# RZT2ME register map
Vendor: Renesas Electronics Corporation; Series: RZT; File version: 1.00.00
CPU: other r0p0, little endian, MPU, no FPU, VTOR, 4 interrupt priority bits, 624 interrupts
Registers are 32-bit, read-write, reset 0x0 unless marked. A register's access mark holds for its fields unless they carry their own. Offsets are from the block's base; [hi:lo] are bit positions; {n}, {i} and the like mark numbered series; 'fields as' and 'values as' point back to an identical list.

## ETHSW (part 1 of 3) — Ethernet Switch
Base 0x80120000
0x00 REVISION ro reset 0x42000600 — Switch Core Version Register
  [31:0] REV — Revision
0x04 SCRATCH
  [31:0] SCRATCH — The Scratch Register provides a memory location to test the register access.
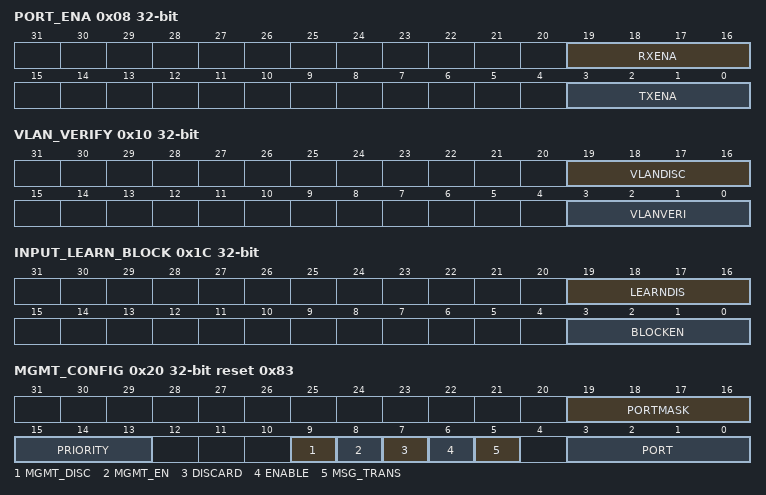
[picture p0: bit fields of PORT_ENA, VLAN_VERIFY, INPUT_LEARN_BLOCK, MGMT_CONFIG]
0x08 PORT_ENA reset not defined — Port Enable Register
  [19:16] RXENA — Receive Enable Mask
  [3:0] TXENA — Transmit Enable Mask
0x0C UCAST_DEFAULT_MASK0 reset 0xF — Unicast Default Mask Register 0
  [3:0] UCASTDM — Default Unicast Resolution
0x10 VLAN_VERIFY — Verify VLAN Domain Register
  [19:16] VLANDISC — Discard Unknown
  [3:0] VLANVERI — Verify VLAN Domain
0x14 BCAST_DEFAULT_MASK0 reset 0xF — Broadcast Default Mask Register 0
  [3:0] BCASTDM — Default Broadcast Resolution
0x18 MCAST_DEFAULT_MASK0 reset 0xF — Multicast Default Mask Register 0
  [3:0] MCASTDM — Default Multicast Resolution
0x1C INPUT_LEARN_BLOCK — Input Learning Block Register
  [19:16] LEARNDIS — Learning Disable
  [3:0] BLOCKEN — Blocking Enable
0x20 MGMT_CONFIG reset 0x83 (reset mask 0xFE0EF) — Management Configuration Register
  [19:16] PORTMASK — Portmask for transmission of management frames. When the management port transmits a frame to the switch, it is forwarded to all ports in this portmask (bit 16 = port 0, bit 17 = port 1, ..., bit 19 = port 3).
  [15:13] PRIORITY — Priority to use for transmitted BPDU frames if non-zero.
  [9] MGMT_DISC — This bit is the same as DISCARD (bit 7) but for the management port.
  [8] MGMT_EN — If set, BPDU frames received at the management port are forwarded to the ports given in the portmask given in this register, bypassing the normal forwarding decisions (except forced forwarding).
  [7] DISCARD — If set, BPDU frames are discarded always.
  [6] ENABLE — If set, all Bridge Protocol Frames (BPDU) are forwarded exclusively to the management port specified in bits [3:0].
  [5] MSG_TRANS — Set (latched) when a BPDU message is transmitted from the management port to any output port. This bit can be used for handshaking to indicate that the port mask bits are used and can now be changed again by setting it to 0.
  [3:0] PORT — The Port number of the port that should act as a management port. Keep the initial value.
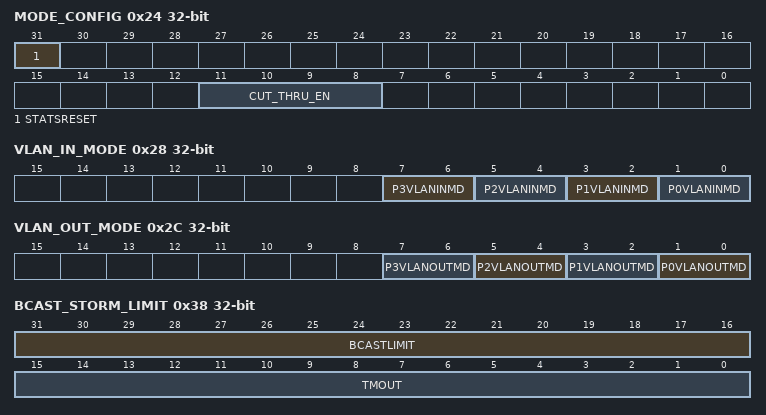
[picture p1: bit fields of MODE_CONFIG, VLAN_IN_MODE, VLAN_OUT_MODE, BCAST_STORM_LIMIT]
0x24 MODE_CONFIG — Mode Configuration Register
  [31] STATSRESET — Reset Statistics Counters Command.
  [11:8] CUT_THRU_EN — Port Cut through Support Enable
0x28 VLAN_IN_MODE — VLAN Input Manipulation Mode Register
  [all] fields
    {v}=Mode {v+1} (v=0..3)
  [7:6] P3VLANINMD — Port3 Define Behavior of VLAN Input Manipulation Function
  [5:4] P2VLANINMD — Port 2 Define Behavior of VLAN Input Manipulation Function
  [3:2] P1VLANINMD — Port 1 Define Behavior of VLAN Input Manipulation Function
  [1:0] P0VLANINMD — Port 0 Define Behavior of VLAN Input Manipulation Function
0x2C VLAN_OUT_MODE — VLAN Output Manipulation Mode Register
  [all] fields
    0=No output manipulation; 1=Mode 1, Strip Mode; 2=Mode 2, Tag Through; 3=Mode 3, Transparent
  [2n+1:2n] P{n}VLANOUTMD (n=0..3) — Port {n} Define Behavior of VLAN Output Manipulation Function
0x30 VLAN_IN_MODE_ENA — VLAN Input Mode Enable Register
  [3:0] VLANINMDEN — Enable the input processing according to the VLAN_IN_MODE for a port (1 bit per port).
0x34 VLAN_TAG_ID reset 0x8100
  [15:0] VLANTAGID — The VLAN type field (TPID) value to expect to identify a VLAN tagged frame.
0x38 BCAST_STORM_LIMIT — Broadcast Storm Protection Register
  [31:16] BCASTLIMIT — Number of broadcast frames (-1) that can be accepted on a port during a timeout period. If more are received, they are discarded. The counter is implemented per port independently. However, the limit is used for all ports.
  [15:0] TMOUT — Timeout in steps of 65535 switch operating clock cycles.
0x3C MCAST_STORM_LIMIT — Multicast Storm Protection Register
  [31:16] MCASTLIMIT — Number of multicast frames (-1) that can be accepted on a port during a timeout period. If more are received, they are discarded. The counter is implemented per port independently. However, the limit is used for all ports.
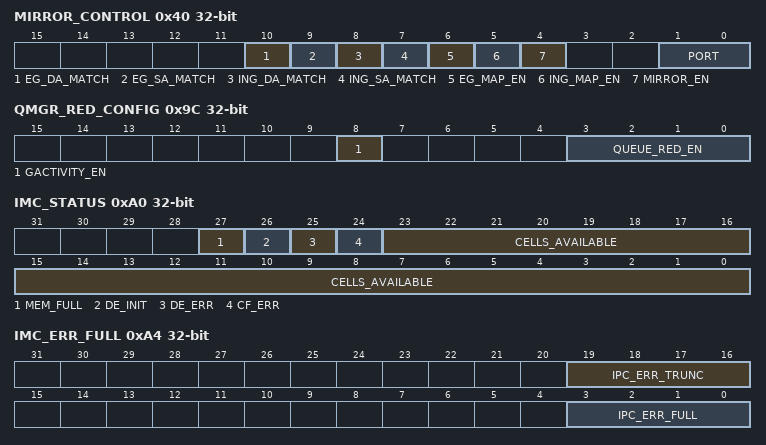
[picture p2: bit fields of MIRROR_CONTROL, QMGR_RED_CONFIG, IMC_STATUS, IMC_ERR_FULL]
0x40 MIRROR_CONTROL — Port Mirroring Configuration Register
  [10] EG_DA_MATCH — If set, only frames transmitted on an egress port with a destination address matching the value programmed in MIRROR_EDST registers are mirrored. Other frames are not mirrored.
  [9] EG_SA_MATCH — If set, only frames transmitted on an egress port with a source address matching the value programmed in MIRROR_ESRC registers are mirrored. Other frames are not mirrored.
  [8] ING_DA_MATCH — If set, only frames received on an ingress port with a destination address matching the value programmed in MIRROR_IDST registers are mirrored. Other frames are not mirrored.
  [7] ING_SA_MATCH — If set, only frames received on an ingress port with a source address matching the value programmed in MIRROR_ISRC registers are mirrored. Other frames are not mirrored.
  [6] EG_MAP_EN — If set, the egress map is enabled (MIRROR_EG_MAP).
  [5] ING_MAP_EN — If set, the ingress map is enabled (MIRROR_ING_MAP).
  [4] MIRROR_EN
    0=Disabled; 1=Enabled
  [1:0] PORT — The port number of the port that acts as the mirror port and receives all mirrored frames. Valid setting range is 0 to 3.
0x44 MIRROR_EG_MAP — Port Mirroring Egress Port Definition Register
  [3:0] EMAP — Port Mirroring Egress Port Definitions
0x48 MIRROR_ING_MAP — Port Mirroring Ingress Port Definition Register
  [3:0] IMAP — Port Mirroring Ingress Port Definitions
0x4C MIRROR_ISRC_0 — Ingress Source MAC Address for Mirror Filtering Register 0
  [31:0] ISRC — Ingress Source MAC Address for Mirror Filtering
0x50 MIRROR_ISRC_1 — Ingress Source MAC Address for Mirror Filtering Register 1
  [15:0] ISRC — Ingress Source MAC Address for Mirror Filtering
0x54 MIRROR_IDST_0 — Ingress Destination MAC Address for Mirror Filtering Register 0
  [31:0] IDST — Ingress Destination MAC Address for Mirror Filtering
0x58 MIRROR_IDST_1 — Ingress Destination MAC Address for Mirror Filtering Register 1
  [15:0] IDST — Ingress Destination MAC Address for Mirror Filtering
0x5C MIRROR_ESRC_0 — Egress Source MAC Address for Mirror Filtering Register 0
  [31:0] ESRC — Egress Source MAC Address for Mirror Filtering
0x60 MIRROR_ESRC_1 — Egress Source MAC Address for Mirror Filtering Register 1
  [15:0] ESRC — Egress Source MAC Address for Mirror Filtering
0x64 MIRROR_EDST_0 — Egress Destination MAC Address for Mirror Filtering Register 0
  [31:0] EDST — Egress Destination MAC Address for Mirror Filtering
0x68 MIRROR_EDST_1 — Egress Destination MAC Address for Mirror Filtering Register 1
  [15:0] EDST — Egress Destination MAC Address for Mirror Filtering
0x6C MIRROR_CNT — Mirror Filtering Count Value Register
  [7:0] CNT — Count Value for Mirror Filtering
0x70 UCAST_DEFAULT_MASK1 reset 0xF — Unicast Default Mask Register 1
  [3:0] UCASTDM1 — Default Unicast Resolution Mask 1
0x74 BCAST_DEFAULT_MASK1 reset 0xF — Broadcast Default Mask Register 1
  [3:0] BCASTDM1 — Default Broadcast Resolution Mask 1
0x78 MCAST_DEFAULT_MASK1 reset 0xF — Multicast Default Mask Register 1
  [3:0] MCASTDM1 — Default Multicast Resolution Mask 1
0x7C PORT_XCAST_MASK_SEL — Port Mask Select Register
  [3:0] MSEL — Mask Select
    0=XCAST_DEFAULT_MASK0 registers are selected; 1=XCAST_DEFAULT_MASK1 registers are selected
0x88 QMGR_ST_MINCELLS — Minimum Memory Cell Statistics Register
  [10:0] STMINCELLS — Minimum Free Cell Indication
0x94 QMGR_RED_MIN4 reset 0xF0F0F0F — RED Minimum Threshold Register
  [31:0] CFGRED_MINTH4 — Random Early Detection (RED) Minimum Threshold for Queues 0 to 3
0x98 QMGR_RED_MAX4 reset 0x2F2F2F2F — RED Maximum Threshold Register
  [31:0] CFGRED_MAXTH4 — Random Early Detection (RED) Maximum Threshold for Queues 0 to 3
0x9C QMGR_RED_CONFIG — RED Configuration Register
  [8] GACTIVITY_EN — Enable Averaging on Global Switch Activity (when this bit is 1) or on port local activity (when this bit is 0) only.
  [3:0] QUEUE_RED_EN — Enable Random Early Detection (RED) (when this bit is 1) or Tail Drop (when this bit is 0) congestion management for a queue.
0xA0 IMC_STATUS ro — Input Memory Controller Status Register
  [27] MEM_FULL — Latched Indication that Memory is or was Full
  [26] DE_INIT — Asserts during Memory Initialization (deallocation module)
  [25] DE_ERR — Deallocation Error
  [24] CF_ERR — Cell Factory Empty Error
  [23:0] CELLS_AVAILABLE — Total number of memory cells (128-byte units) available in the shared memory (real time).
0xA4 IMC_ERR_FULL ro — Input Port Memory Full and Truncation Indicator Register
  [19:16] IPC_ERR_TRUNC — Memory became full while a frame was received and was partly written into memory.
  [3:0] IPC_ERR_FULL — Memory was full at start of a frame reception.
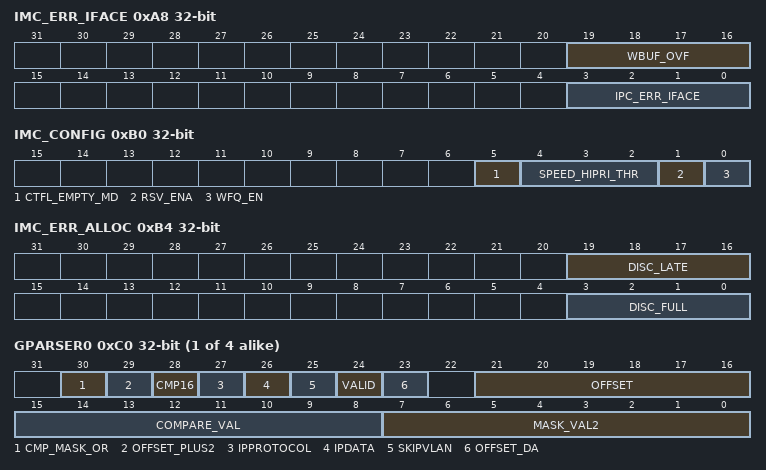
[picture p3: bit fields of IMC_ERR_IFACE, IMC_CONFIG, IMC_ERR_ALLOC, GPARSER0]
0xA8 IMC_ERR_IFACE ro — Input Port Memory Error Indicator Register
  [19:16] WBUF_OVF — Error indicating an overflow in the input write buffer to the memory controller (a small decoupling FIFO at every MAC RX).
  [3:0] IPC_ERR_IFACE — Error indication on memory input (receive from MAC) that a frame has been truncated and discarded.
0xAC IMC_ERR_QOFLOW ro — Output Port Queue Overflow Indicator Register
  [3:0] OP_ERR — A frame cannot be stored in an output queue of the port as the queue FIFO overflowed (write occurred into full fifo). The frame is ignored but stays stored in memory. This should not occur during normal operation. This is a fatal error as the memory allocated by that frame is not freed, and resulting in memory leakage.
0xB0 IMC_CONFIG — Input Memory Controller Configuration Register
  [5] CTFL_EMPTY_MD — When this bit is set to 0, a frame received in Cut-Through mode that cannot allocate an entry in the CTFL is forwarded as store and forward.
  [4:2] SPEED_HIPRI_THR — High-Priority Speed Threshold
  [1] RSV_ENA — Enable Memory Reservations to Operate
  [0] WFQ_EN — Enable weighted fair queuing (when this bit is 1) or strict priority (when this bit is 0, default) output queue scheduling.
0xB4 IMC_ERR_ALLOC ro — Input Port Error Indicator Register
  [19:16] DISC_LATE — Per port discard indication due to lateness in the priority resolution. The priority resolution can be delayed by the pattern matchers. If it arrives too late (after approximately 100 bytes into the frame), the frame is discarded.
  [3:0] DISC_FULL — Per port discard indication due to memory pool going empty. Per port indication that one of the queues was full and a frame was discarded.
{0xC0+4i} GPARSER{i} (i=0..3) — [n + 1]th Parser of 1st Block
  [30] CMP_MASK_OR — Use the MASK_VAL2[7:0] bits as a 2nd compare value. When set, the parser reports a match if the byte at given offset matches COMPARE_VAL[7:0] or MASK_VAL2[7:0].
  [29] OFFSET_PLUS2 — Repeats the comparison at offset + 2, if the comparison at offset failed.
  [28] CMP16 — When set, MASK_VAL2[7:0] is used as a value to perform a 16-bit compare. COMPARE_VAL[7:0] represent the byte at the given offset and MASK_VAL2[7:0] represent the byte following at offset + 1 which matches the network byte order for 16-bit fields. For example, setting a compare value of 0x0800 and offset 0 matches IP frames. No mask is available in this mode.
  [27] IPPROTOCOL — When set, the compare value is compared with the protocol field found within the IP header for both IPv4 and IPv6 frames. It implicitly acts as SKIPVLAN = 1 skipping any VLAN tags if present. The offset setting has no meaning and is ignored.
  [26] IPDATA — When set, the offset starts with the first byte following an IP header if an IP frame is processed. The following fields are skipped:
  [25] SKIPVLAN — When set, any optional VLAN tags found in the frame are skipped and the parser starts operating at the first byte following any VLAN tags. When cleared, the parser starts with the first byte following the source MAC address.
  [24] VALID — Indicate that this entry is valid (when this bit is 1) and should be used. When this bit is 0, the parser result always indicates "no match" and none of the other bits are relevant.
  [23] OFFSET_DA — When set, the offset starts counting from the first byte of the MAC destination address.
  [21:16] OFFSET — An offset in bytes where to find the data for comparison within the frame. The offset value starts at 0 to indicate the very first byte after offset start. The offset start can be either the type/length field of the frame, that is, 0 = first byte of type/length field) or the payload following an IP header (see IPDATA). Valid values range from 0 to 60.
  [15:8] COMPARE_VAL — The value to compare the frame data with at the given offset.
  [7:0] MASK_VAL2 — Mask for single byte compares or 2nd compare value (if bit 30 = 1) or least significant bits of a 16-bit compare value (if bit 28 = 1). When used as a mask (bit 28, 30 = 0, 0), the data from the frame is ANDed with this mask, then compared to the compare value. All bits having a 1 in the mask will be compared with the data in the frame. All bits having a 0 will be 0 for the compare, however this requires the compare value to have those bits also set to 0.
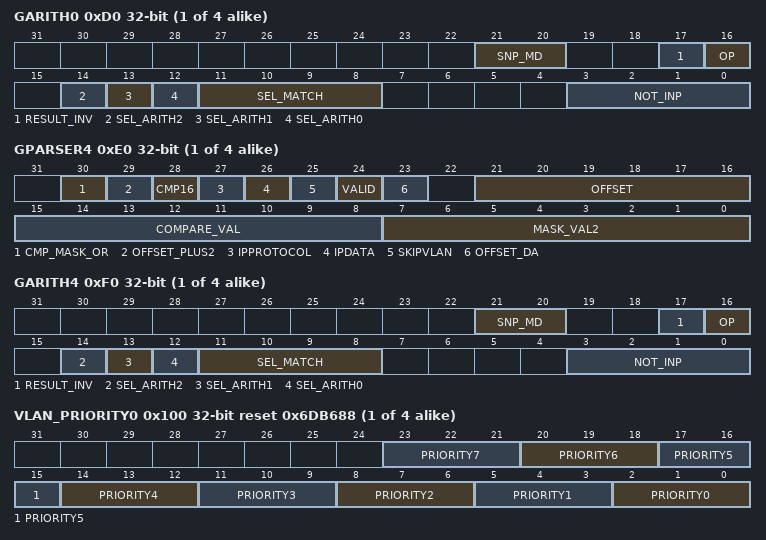
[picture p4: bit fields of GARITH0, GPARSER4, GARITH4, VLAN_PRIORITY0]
{0xD0+4i} GARITH{i} (i=0..3) — Snoop Configuration for Arithmetic [n + 1]th Stage of 1st Block
  [21:20] SNP_MD — Snoop Mode
    0=Disabled, no snooping occurs (forward normally); 1=Forward to designated management port only; 2=Forward normally and copy to management port; 3=Discard the frame
  [17] RESULT_INV — Result Invert
    0=The output is used directly; 1=The output of this stage is inverted
  [16] OP — Operation
    0=AND all selected inputs; 1=OR all selected inputs
  [14] SEL_ARITH2 — Select Arithmetic Stage 2
  [13] SEL_ARITH1 — Select Arithmetic Stage 1
  [12] SEL_ARITH0 — Select Arithmetic Stage 0
  [11:8] SEL_MATCH — Select Match
  [3:0] NOT_INP — Not Input
{0xD0+4i} GPARSER{i} (i=4..7) — [n - 3]th Parser of 2nd Block
  [30] CMP_MASK_OR — Use MASK_VAL2[7:0] as a second compare value. When set, the parser reports a match if the byte at given offset matches COMPARE_VAL[7:0] or MASK_VAL2[7:0].
  [29] OFFSET_PLUS2 — Repeats the comparison at offset + 2, if the comparison at offset failed.
  [28] CMP16 — When set, MASK_VAL2[7:0] is used as a value to perform a 16-bit compare. COMPARE_VAL[7:0] represents the byte at the given offset and MASK_VAL2[7:0] represents the byte following at offset + 1 which matches the network byte order for 16-bit fields, (for example setting a compare value of 0x0800 and offset 0 matches IP frames). No mask is available in this mode.
  [27] IPPROTOCOL — When set, the compare value is compared with the protocol field located within the IP header for both IPv4 and IPv6 frames. It implicitly acts as SKIPVLAN = 1 skipping any VLAN tags if present. The offset setting has no meaning and is ignored. If the bit is set, but the frame is not an IPv4/v6 frame the parser reports a no match and does not continue to inspect the frame. When cleared, the offset is used normally on all frames.
  [26] IPDATA — When set, the offset starts with the first byte following an IP header if an IP frame is processed. The following fields are skipped:
  [25] SKIPVLAN — When set, any optional VLAN tags found in the frame are skipped and the parser starts operating at the first byte following any VLAN tags. When cleared, the parser starts with the first byte following the source MAC address.
  [24] VALID — Indicates that this entry is valid (when this bit is 1) and should be used. When this bit is 0, the parser result always indicates "no match" and none of the other bits are relevant.
  [23] OFFSET_DA — When set, the offset starts counting from the first byte of the MAC destination address.
  [21:16] OFFSET — An offset in bytes to locate the data for comparison within the frame. The offset value starts at 0 to indicate the very first byte after offset start. The offset start can be either the type or length field of the frame, for example 0 = first byte of type/length field) or the payload following an IP header (see bit 26). Valid values range from 0 to 60.
  [15:8] COMPARE_VAL — The value to compare the frame data with at the given offset.
  [7:0] MASK_VAL2 — Mask for single byte compares or 2nd compare value (if bit 30 = 1) or least significant bits of a 16-bit compare value (if bit 28 = 1). When used as a mask (bit 28, 30 = 0, 0), the data from the frame is ANDed with this mask, then compared to the compare value. All bits having a 1 in the mask are compared with the data in the frame. All bits having a 0 will be 0 for the compare, however this requires the compare value to have those bits also set to 0.
{0xE0+4i} GARITH{i} (i=4..7) — Snoop Configuration for Arithmetic [n - 3]th Stage of 2nd Block
  fields as GARITH0
{0x100+4i} VLAN_PRIORITY{i} (i=0..3) reset 0x6DB688 — VLAN Priority Register {i}
  [3n+2:3n] PRIORITY{n} (n=0..7) — Priority {n} Setting
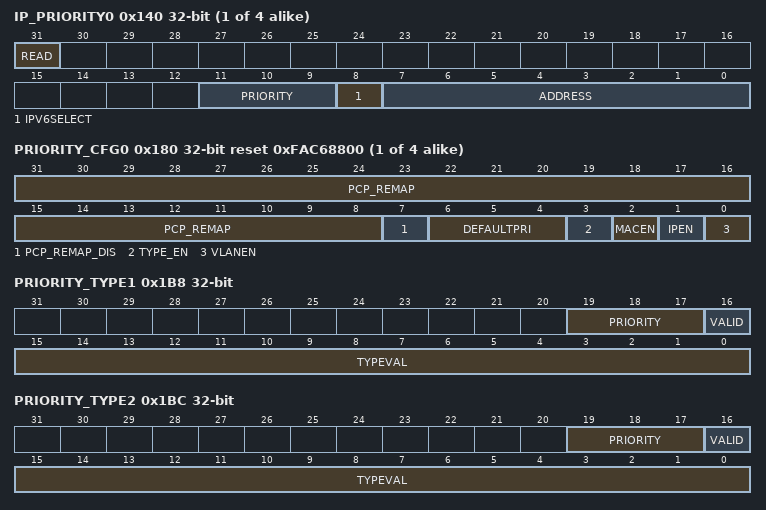
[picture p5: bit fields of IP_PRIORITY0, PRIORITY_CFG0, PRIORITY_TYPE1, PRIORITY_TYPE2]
{0x140+4i} IP_PRIORITY{i} (i=0..3) — IP Priority Register {i}
  [31] READ — COS Table Operation Switching
    0=Write the priority information to the COS table; 1=Does not write the priority information to the COS table (unchanged)
  [11:9] PRIORITY — COS Table Priority
  [8] IPV6SELECT — IPv6 COS Table Selection
    0=The IPv4 table is accessed. The valid range of the ADDRESS[7:0] bits is from 0 to 63.; 1=The IPv6 table is accessed. The valid range of the ADDRESS[7:0] bits is from 0 to 255.
  [7:0] ADDRESS — COS Table Address Specifying
{0x180+4i} PRIORITY_CFG{i} (i=0..3) reset 0xFAC68800 — Priority Configuration Register {i}
  [31:8] PCP_REMAP — PCP Remapping function
  [7] PCP_REMAP_DIS — Disables PCP remapping when set to 1.
  [6:4] DEFAULTPRI — Default Priority Enable Setting
  [3] TYPE_EN — TYPE Based Priority Enable
    0=Type fields are ignored; 1=The type/length field of the frame (following any VLAN tags) is compared to all PRIORITY_TYPE configured values. If any of the values matches, the priority information from that matching type is used.
  [2] MACEN — MAC Based Priority Enable
    0=MAC priority is ignored; 1=Priority information found within the MAC address table (for a static entry)
  [1] IPEN — IP Priority Enable
    0=IP priority is not used and IP DiffServ/COS fields of the frame are ignored; 1=Priority in the switch is determined using the IP DiffServ/COS field according to the IP_PRIORITYn setting for the port on which the frame was received
  [0] VLANEN — VLAN Priority Enable
    0=VLAN priority is not used. The priority field of the VLAN tag of a frame is ignored.; 1=Priority in the switch is determined using the priority field of the VLAN tag of a frame according to the VLAN_PRIORITYn setting for the port on which the frame was received
0x1B8 PRIORITY_TYPE1 — Priority Type Register 1
  [19:17] PRIORITY — The priority value to use if a match occurs.
  [16] VALID — If set indicates, this register contains valid data.
  [15:0] TYPEVAL — Type Priority
0x1BC PRIORITY_TYPE2 — Priority Type Register 2
  fields as PRIORITY_TYPE1
0x1C0 MGMT_ADDR0_lo reset 0xC28001 — Lower MAC Address 0 for Bridge Protocol Frame Register
  [31:0] BPDU_DST — Additional MAC address defining a Bridge Protocol Frame (BPDU) in addition to the commonly-known addresses
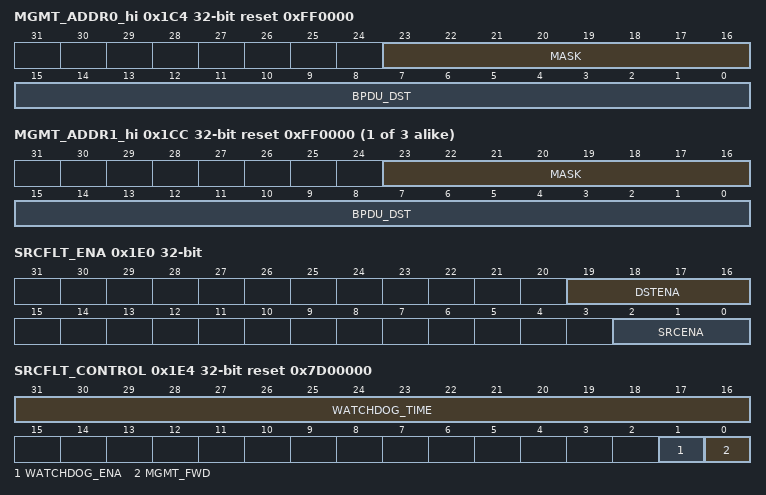
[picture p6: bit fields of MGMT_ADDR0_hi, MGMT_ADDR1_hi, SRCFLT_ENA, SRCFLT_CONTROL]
0x1C4 MGMT_ADDR0_hi reset 0xFF0000 — Higher MAC Address 0 for Bridge Protocol Frame Register
  [23:16] MASK — 8-bit mask for comparing the last byte of the MAC address.
  [15:0] BPDU_DST — Bits [7:0] is 5th byte, bits [15:8] is 6th (last) byte
0x1C8 MGMT_ADDR1_lo reset 0xC28001 — Lower MAC Address 1 for Bridge Protocol Frame Register
  fields as MGMT_ADDR0_lo
{0x1C4+8i} MGMT_ADDR{i}_hi reset 0xFF0000 (i=1..3) — Higher MAC Address {i} for Bridge Protocol Frame Register
  [23:16] MASK — 8-bit mask for comparing the last byte of the MAC address.
  [15:0] BPDU_DST — Bits [7:0] is 5th byte, bits [15:8] is 6th (last) byte.
0x1D0 MGMT_ADDR2_lo reset 0xC28001 — Lower MAC Address 2 for Bridge Protocol Frame Register
  [31:0] BPDU_DST — Additional MAC address defining a Bridge Protocol Frame (BPDU) in addition to the commonly-known addresses.
0x1D8 MGMT_ADDR3_lo reset 0xC28001 — Lower MAC Address 3 for Bridge Protocol Frame Register
  fields as MGMT_ADDR2_lo
0x1E0 SRCFLT_ENA — MAC Source Address Filtering Enable Register
  [19:16] DSTENA — Per-Destination Port Enable
  [2:0] SRCENA — Per-Source Port Enable
0x1E4 SRCFLT_CONTROL reset 0x7D00000 — MAC Source Address Filtering Control Register
  [31:16] WATCHDOG_TIME — Defines the watchdog expire time in milliseconds. The default is 2000 milliseconds.
  [1] WATCHDOG_ENA — When set to 1, a watchdog is enabled.
  [0] MGMT_FWD — Management Forward Enable
0x1E8 SRCFLT_MACADDR_LO — Lower MAC Filtering Address Register
  [31:0] SRCFLT_MACADDR — MAC address to use in source filtering
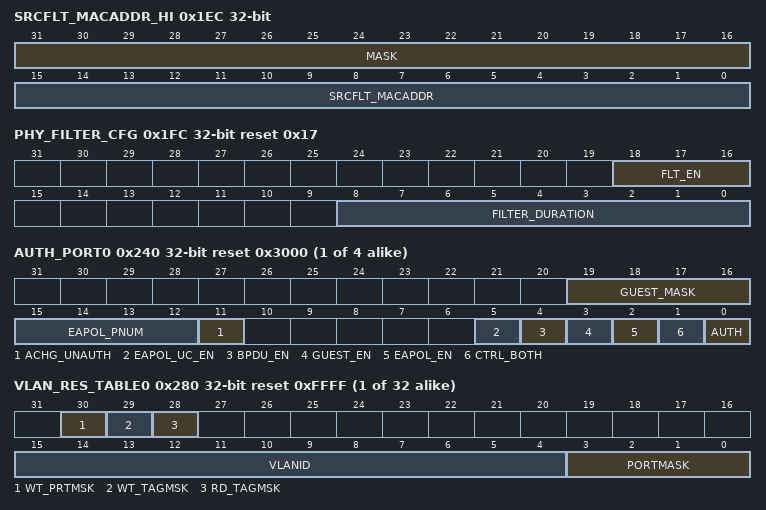
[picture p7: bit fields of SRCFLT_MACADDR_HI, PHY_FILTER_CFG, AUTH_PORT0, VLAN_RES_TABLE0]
0x1EC SRCFLT_MACADDR_HI — Higher MAC Filtering Address Register
  [31:16] MASK — The mask to apply to the last 16 bits of the MAC address
  [15:0] SRCFLT_MACADDR — MAC address to use in source filtering
0x1FC PHY_FILTER_CFG reset 0x17 — Debounce Filter Configuration Register
  [18:16] FLT_EN — Per-port Enable Mask
  [8:0] FILTER_DURATION — This is the amount of time to wait after the last phy_link (ETHSW_PHYLINKn: n = port) transition from 0 to 1 to acknowledge the link-up condition.
{0x200+4i} SYSTEM_TAGINFO{i} (i=0..3) — One VLAN ID Field {i} for VLAN Input Manipulation
  [15:0] SYSVLANINFO — System VLAN Info (prio/cfi/vid) for Port n
{0x240+4i} AUTH_PORT{i} (i=0..3) reset 0x3000 (reset mask 0xFF83E) — Port {i} Authentication Control and Configuration
  [19:16] GUEST_MASK — Destination port mask with all ports that are allowed to receive non-EAPOL frames from this port while it is unauthorized and guest (GUEST_EN) is enabled.
  [15:12] EAPOL_PNUM — EAPOL Port Number
  [11] ACHG_UNAUTH — Automatic Port Change to Unauthorized
  [5] EAPOL_UC_EN — EAPOL Unicast Enable
  [4] BPDU_EN — BPDU Enable
  [3] GUEST_EN — Guest Enable
  [2] EAPOL_EN — EAPOL Enable
  [1] CTRL_BOTH — Controlled Both
    0=The port operates in Controlled Directions (mode in). This allows frames from other ports to be forwarded to this port for transmission, but reception is still restricted.; 1=The port operates in Controlled Directions (mode both). This means other ports cannot transmit any traffic on this port, except the port specified in the EAPOL destination port.
  [0] AUTH — Authorized
    0=The port is unauthorized restricting forwarding according to the rules configured in this register; 1=The port is in the authorized state and operates normally without restrictions. The other bits of this register, except for bits [15:12] and bit [2], are not relevant.
{0x280+4i} VLAN_RES_TABLE{i} (i=0..31) reset 0xFFFF — 32 VLAN Domain Entries
  [30] WT_PRTMSK — Write Port Mask
  [29] WT_TAGMSK — Write TAG Mask
  [28] RD_TAGMSK — Read TAG Mask
    0=The port mask is returned; 1=The tagged bit mask is returned
  [15:4] VLANID — The 12-bit VLAN identifier (VLAN ID) of the entry.
  [3:0] PORTMASK — When this bit is set to 1, it defines a port as a member of the VLAN. When bit [28] or bit [29] is set, the tagged bit mask is read/written instead of port mask.
0x300 TOTAL_DISC ro — Discarded Frame Total Number Register
  [31:0] TOTAL_DISC — Total number of incoming frames accepted by MAC RX but discarded in the switch
0x304 TOTAL_BYT_DISC ro — Discarded Frame Total Bytes Register
  [31:0] TOTAL_BYT_DISC — Sum of bytes of frames counted in TOTAL_DISC
0x308 TOTAL_FRM ro — Processed Frame Total Number Register
  [31:0] TOTAL_FRM — Total number of incoming frames processed by the switch
0x30C TOTAL_BYT_FRM ro — Processed Frame Total Bytes Register
  [31:0] TOTAL_BYT_FRM — Sum of bytes of frames counted in TOTAL_FRM
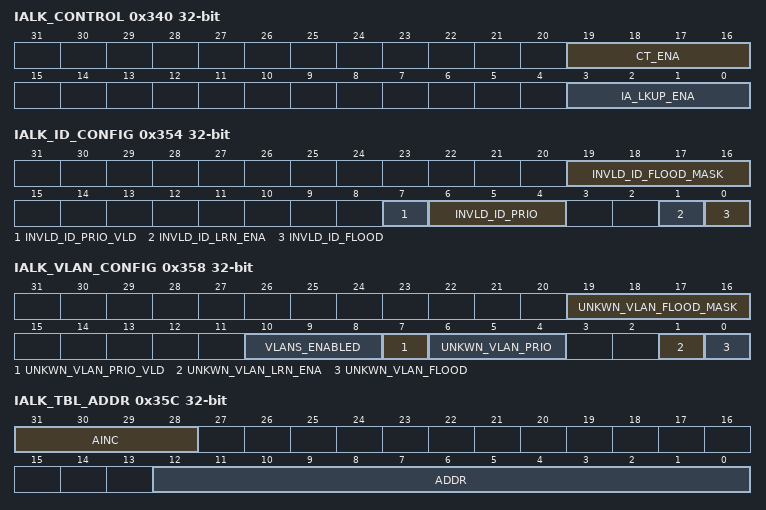
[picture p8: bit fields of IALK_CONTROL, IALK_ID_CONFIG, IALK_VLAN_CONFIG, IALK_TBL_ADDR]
0x340 IALK_CONTROL — IA Lookup Function Enable Register
  [19:16] CT_ENA — Per-port Cut-Through Mode Enable
  [3:0] IA_LKUP_ENA — Per-port Enable to the IA Lookup Table
0x344 IALK_OUI reset 0xCF0E01 — IA Frames MAC Address OUI Register
  [23:0] IALK_OUI — IA Frames MAC Address OUI
0x348 IALK_ID_MIN — Minimum Value ID MAC Address Register
  [23:0] IALK_ID_MIN — Minimum value for the 24-bit ID in the MAC address
0x34C IALK_ID_MAX reset 0xFFFFFF — Maximum Value ID MAC Address Register
  [23:0] IALK_ID_MAX — Maximum value for the 24-bit ID in the MAC address
0x350 IALK_ID_SUB — Offset Value ID MAC Address Register
  [23:0] IALK_ID_SUB — Offset value to subtract from the 24-bit ID in the MAC address
0x354 IALK_ID_CONFIG — Configures Lookup Response Unknown IDs Register
  [19:16] INVLD_ID_FLOOD_MASK — Forwarding mask used for frames whose ID is invalid. This bit is only valid when INVLD_ID_FLOOD bit is set to 1. Setting this mask to 0 causes the frame to be dropped.
  [7] INVLD_ID_PRIO_VLD — Indicates if the priority in INVLD_ID_PRIO is valid. This bit is valid only when INVLD_ID_FLOOD bit is set to 1.
  [6:4] INVLD_ID_PRIO — Priority to use for found responses of an invalid ID. This bit is only valid when INVLD_ID_FLOOD bit is set to 1.
  [1] INVLD_ID_LRN_ENA — Setting this bit to 1 allows automatic learning into the L2 FDB for frames with unknown IDs. When 0, learning is inhibited. This bit is only valid when INVLD_ID_FLOOD bit is set to 1.
  [0] INVLD_ID_FLOOD — Setting this bit to 1 causes the IA table to return a found response for frames whose ID lies outside the ID range defined by [IA_LK_MAX:IA_LK_MIN] using INVLD_ID_FLOOD_MASK[3:0] bits.
0x358 IALK_VLAN_CONFIG — Configure Lookup Response Unknown VLAN Register
  [19:16] UNKWN_VLAN_FLOOD_MASK — Forwarding mask used for frames with an unknown VLAN ID.
  [10:8] VLANS_ENABLED — Configures the logical geometry of the IA table by specifying the number of distinct VLAN IDs enabled. When set to 0, no VLANs are supported and the VLAN ID for the frames is ignored.
  [7] UNKWN_VLAN_PRIO_VLD — Indicates if the priority in UNKWN_VLAN_PRIO[2:0] is valid. This bit is only valid when UNKWN_VLAN_FLOOD bit is set to 1.
  [6:4] UNKWN_VLAN_PRIO — Priority to use for found responses for an unknown VLAN. This bit is only valid when UNKWN_VLAN_FLOOD bit is set to 1.
  [1] UNKWN_VLAN_LRN_ENA — Setting this bit to 1 allows automatic learning into the L2 FDB for frames with unknown VLANs. When 0, learning is inhibited. This bit is only valid when UNKWN_VLAN_FLOOD bit is set to 1.
  [0] UNKWN_VLAN_FLOOD — When this bit is set to 1, a frame matching the OUI and with a valid ID but having a VLAN ID not matching any of the enabled values in IALK_VLANIDn causes the IA table to return a found response using the forwarding mask in UNKWN_VLAN_FLOOD_MASK[3:0].
0x35C IALK_TBL_ADDR — IA Lookup Database Address Register
  [31:28] AINC — Auto-Increment Control
  [12:0] ADDR — Defines the address to write to or read from the IA Lookup table
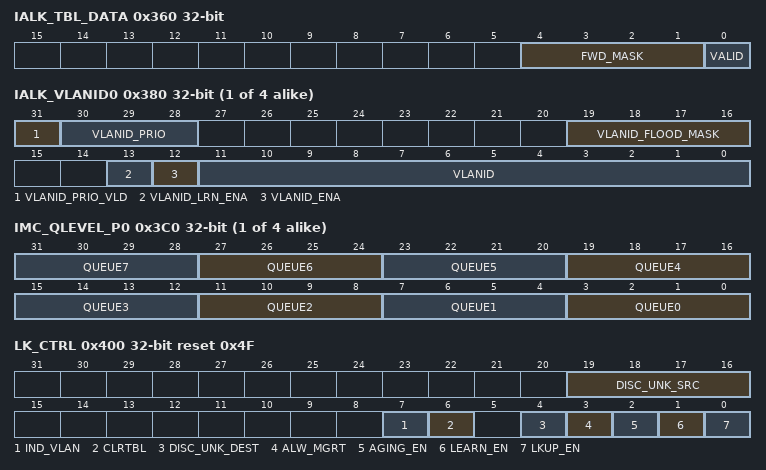
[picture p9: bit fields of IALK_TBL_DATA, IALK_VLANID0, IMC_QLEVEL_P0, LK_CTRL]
0x360 IALK_TBL_DATA — IA Lookup Database Data Register
  [4:1] FWD_MASK — Forwarding mask used for lookups that hit the entry and when VALID is set to 1.
  [0] VALID — Indicates whether the entry indicated by ADDR is valid or not.
{0x380+4i} IALK_VLANID{i} (i=0..3) — IA Lookup VLANIDn Register
  [31] VLANID_PRIO_VLD — Indicates if the priority in VLANID_PRIO[2:0] is valid.
  [30:28] VLANID_PRIO — Priority to use for found responses.
  [19:16] VLANID_FLOOD_MASK — Flooding mask to be used for frames matching this VLAN ID but with an invalid entry in the IA table.
  [13] VLANID_LRN_ENA — Configures whether automatic learning in the L2 FDB is allowed for frames matching VLAN ID. This also includes frames that match the VLAN ID and that the entry in the IA table is invalid.
  [12] VLANID_ENA — Enables this VLAN ID. When set to 1, the VLAN ID of the frame is compared against VLANID[11:0].
  [11:0] VLANID — Configure the VLAN ID to be used for VLAN n (n: IALK_VLAN_CONFIG.VLANS_ENABLED). This bit is only valid when VLANID_ENA bit is set to 1. A value of 0 matches any VLAN ID.
{0x3C0+4i} IMC_QLEVEL_P{i} (i=0..3) ro — Port {i} Queued Frame Count Register
  [4n+3:4n] QUEUE{n} (n=0..7) — A 4-bit value per queue indicating the number of frames stored in queue {n}
0x400 LK_CTRL reset 0x4F — Learning/Lookup Function Global Configuration Register
  [19:16] DISC_UNK_SRC — Discard Unknown Source
  [7] IND_VLAN — Enable Independent VLAN Learning
  [6] CLRTBL — Clear Table
  [4] DISC_UNK_DEST — Discard Unknown Destination
  [3] ALW_MGRT — Allow Migration
  [2] AGING_EN — Aging Enable
  [1] LEARN_EN — Learning Enable
  [0] LKUP_EN — Lookup Controller Enable
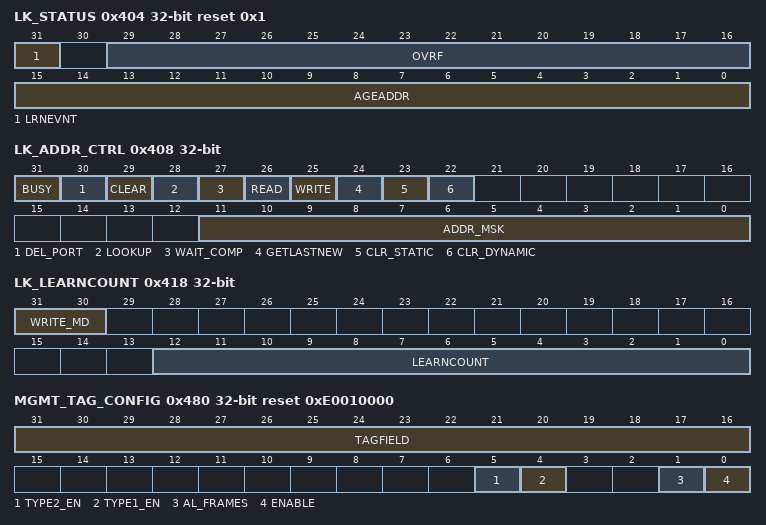
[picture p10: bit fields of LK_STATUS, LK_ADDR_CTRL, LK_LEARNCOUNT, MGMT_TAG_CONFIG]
0x404 LK_STATUS reset 0x1 — Status Bits and Table Overflow Counter Register
  [31] LRNEVNT — Learn Event
  [29:16] OVRF — Counts number of table overflows that occurred (a new address was learned but the table had no storage and an older entry was deleted). The counter is cleared by writing into the register and having bit 16 set to 1.
  [15:0] AGEADDR ro — Address the aging process will inspect when the aging timer expires next time.
0x408 LK_ADDR_CTRL — Address Table Transaction Control and Read/Write Address
  [31] BUSY ro — Transaction Busy Indication
  [30] DEL_PORT — When set to 1, scans the complete table for valid dynamic entries that contain the given ports in their destination port mask and deletes the ports or the complete entry. The port mask is provided in the ADDR_MSK[3:0] when writing this register (1 bit per port, bit 0 = port 0, bit 1 = port 1, and so on).
  [29] CLEAR — When set to 1, writes all 0s to the entry selected by the given address set in ADDR_MSK[11:0]. If this bit is set together with the LOOKUP bit, first a lookup is performed and if the lookup succeeds, the entry is then deleted. The registers LK_DATA_LO/HI/HI2 are also cleared. The memory address in this register is set from the lookup result. If the lookup failed, the clear command is ignored and memory address is arbitrary.
  [28] LOOKUP ro — When set to 1, perform a lookup of the MAC address given in LK_DATA_LO/HI/HI2.
  [27] WAIT_COMP — When set to 1, instructs to stall the processor bus until the transaction is completed. This allows performing of consecutive writes into this register with varying commands without the need for polling the BUSY bit.
  [26] READ — When set to 1, perform a single read transaction.
  [25] WRITE — When set to 1, perform a single write transaction.
  [24] GETLASTNEW — When set to 1, retrieves the last source address that was not found in the table and places it into LK_DATA_LO/HI/HI2. The valid bit of the entry (bit LK_DATA_HI[16]) indicates if the address is new (when valid bit is 1) or not (when valid bit is 0) since the command was last issued.
  [23] CLR_STATIC — When set to 1, scans the complete table for valid static entries and deletes them (writes entry with all 0s). This bit is cleared when the function has completed.
  [22] CLR_DYNAMIC — When set to 1, scans the complete table for valid dynamic entries and deletes them (writes entry with all 0s). This bit is cleared when the function has completed.
  [11:0] ADDR_MSK — Memory address for read and write transactions. This is the address of a 69-bit entry. For the DEL_PORT bit, a port mask can be provided in these bits instead of the address. Bit 0 represents port 0, bit 1 port 1, and so on.
0x40C LK_DATA_LO — Lower 32-Bit Data of Lookup Memory Entry
  [31:0] MEMDATA — Memory Data [31:0]
0x410 LK_DATA_HI — Higher 25-Bit Data of Lookup Memory Entry
  [24:0] MEMDATA — Memory Data [56:32]
0x414 LK_DATA_HI2 — Higher2 12-Bit Data of Lookup Memory Entry
  [19:8] MEMDATA — Memory Data [68:57]
0x418 LK_LEARNCOUNT — Learned Address Count Register
  [31:30] WRITE_MD — These bits define how the LEARNCOUNT value is modified when writing into the register:
    0=Sets LEARNCOUNT to given value; 1=Increments the LEARNCOUNT value by 1 (atomic); 2=Decrements the LEARNCOUNT value by 1 (atomic); 3=Reserved, write has no effect on LEARNCOUNT
  [12:0] LEARNCOUNT — Number of Learned Addresses
0x41C LK_AGETIME reset 0x4000 — Period of the Aging Timer
  [23:0] AGETIME — 24-bit Timer Value
0x480 MGMT_TAG_CONFIG reset 0xE0010000 — Management Tag Configuration Register
  [31:16] TAGFIELD — The value of the tag that is found in the first Type/Length field of the frame to identify that the control information is present within a frame. For example, [31:24] = first octet, [23:16] = 2nd octet.
  [5] TYPE2_EN — When set, frames with a Type field that match the value in PRIORITY_TYPE2.TYPEVAL[15:0] have management tag inserted. This is in addition to BPDU frames which always have tag inserted.
  [4] TYPE1_EN — When set, frames with a Type field that match the value in PRIORITY_TYPE1.TYPEVAL[15:0] have management tag inserted. This is in addition to BPDU frames which always have tag inserted.
  [1] AL_FRAMES — Enable Tag Insertion for All Frames
  [0] ENABLE — Enable Management Tag Insertion Module
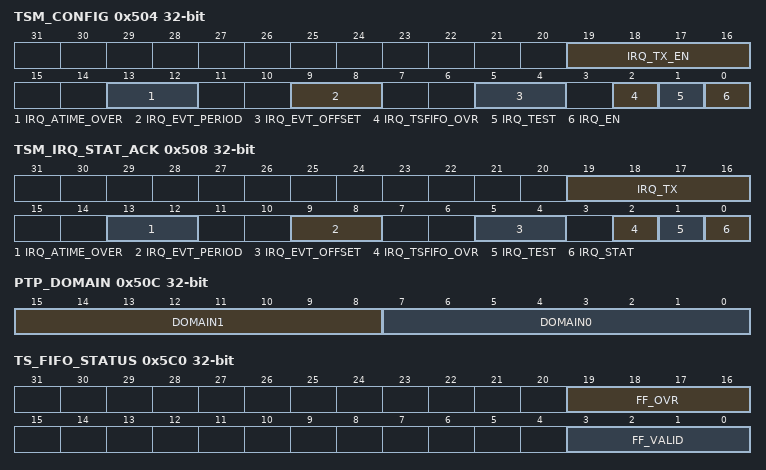
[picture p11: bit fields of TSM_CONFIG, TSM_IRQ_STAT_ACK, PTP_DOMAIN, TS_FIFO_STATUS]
0x504 TSM_CONFIG — Timestamping Control Module Configuration Register
  [19:16] IRQ_TX_EN — Per Port Transmit Timestamp Capture Interrupt Enable
  [13:12] IRQ_ATIME_OVER — Per-timer Trigger interrupt enable for the timer wrap (reached its maximum)
  [9:8] IRQ_EVT_PERIOD — Per-timer Trigger interrupt enable for the timer periodical event
  [5:4] IRQ_EVT_OFFSET — Per-timer Trigger interrupt enable for the timer offset event
  [2] IRQ_TSFIFO_OVR — Trigger interrupt enable for Transmit Timestamp Capture Overflow event
  [1] IRQ_TEST — Software controlled interrupt for testing purposes
  [0] IRQ_EN — Final Interrupt enable
0x508 TSM_IRQ_STAT_ACK — Interrupt Status/Acknowledge Register
  [19:16] IRQ_TX — Per Port Transmit Timestamp Capture Interrupt
  [13:12] IRQ_ATIME_OVER — Per-timer Overflow Interrupt Pending Status
  [9:8] IRQ_EVT_PERIOD — Per-timer Periodical Interrupt Pending Status
  [5:4] IRQ_EVT_OFFSET — Per-timer Offset Interrupt Pending Status
  [2] IRQ_TSFIFO_OVR ro — Transmit Timestamp Capture Overflow Interrupt Pending Status
  [1] IRQ_TEST — Test Interrupt Pending Status
  [0] IRQ_STAT ro — Interrupt Pending Status
0x50C PTP_DOMAIN — Domain Number of PTP Frame
  [15:8] DOMAIN1 — DomainNumber to Match Against for Timer 1
  [7:0] DOMAIN0 — DomainNumber to Match Against for Timer 0
{0x540+0x10*i} PEERDELAY_P{i}_T0 (i=0..3) — Port {i} Peer Delay Value for Timer 0 (n = 0 to 3)
  [29:0] PEERDELAY — Peer Delay Value Determined at the Port n for Timer 0
{0x544+0x10*i} PEERDELAY_P{i}_T1 (i=0..3) — Port {i} Peer Delay Value for Timer 1 (n = 0 to 3)
  [29:0] PEERDELAY — Peer Delay Value Determined at the Port n for Timer 1
0x5C0 TS_FIFO_STATUS — Transmit Timestamp FIFO Status Register
  [19:16] FF_OVR — Per-port indication that a timestamp cannot be written to the FIFO because of the FIFO being full.
  [3:0] FF_VALID ro — Per-port indication that a valid timestamp is available in the corresponding FIFO of the port
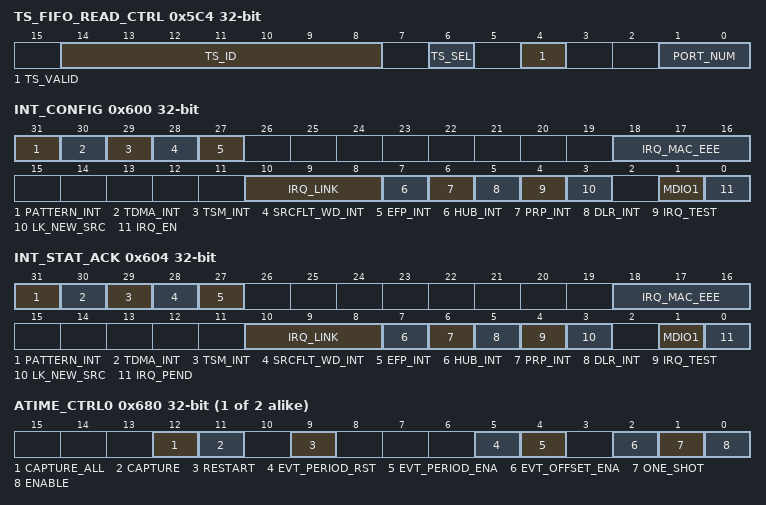
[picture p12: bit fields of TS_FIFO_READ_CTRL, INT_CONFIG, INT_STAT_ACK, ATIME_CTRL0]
0x5C4 TS_FIFO_READ_CTRL — Transmit Timestamp FIFO Read Control Register
  [14:8] TS_ID ro — When TS_VALID is 1, TS_ID indicates the ID specified by the application through the management tag control information, if present.
  [6] TS_SEL ro — When TS_VALID is 1, TS_SEL indicates the timer used for the read timestamp.
  [4] TS_VALID ro — When reading from this register, this bit is 1 if the FIFO indicated by PORT_NUM contained valid data.
  [1:0] PORT_NUM — Port Number to Read from
0x5C8 TS_FIFO_READ_TIMESTAMP ro — 32-bit Timestamp Value Read from FIFO
  [31:0] TIMESTAMP — 32-bit timestamp value read from the FIFO
0x600 INT_CONFIG — Interrupt Enable Configuration Register
  [31] PATTERN_INT — Enable Interrupt for RX Pattern Matcher
  [30] TDMA_INT — Enable Interrupt for TDMA scheduler
  [29] TSM_INT — Enable Interrupt for TSM (Timer, Timestamping)
  [28] SRCFLT_WD_INT — MAC Address Source Filtering Watchdog
  [27] EFP_INT — Enable Interrupt for Extended Frame Parser
  [18:16] IRQ_MAC_EEE — Per Line Port MAC interrupt
  [10:8] IRQ_LINK — Per Line Port Phy Link Change Interrupt Enable
  [7] HUB_INT — Enable Interrupt for HUB
  [6] PRP_INT — Enable Interrupt for PRP
  [5] DLR_INT — Enable Interrupt for DLR
  [4] IRQ_TEST — When set, an interrupt is triggered immediately. Can be used to cause a software controlled interrupt for testing purposes.
  [3] LK_NEW_SRC — Enable Interrupt for New Source Address
  [1] MDIO1 — Enable Interrupt on Transaction Complete from MDIO Controller
  [0] IRQ_EN — Interrupt Global Enable
0x604 INT_STAT_ACK — Interrupt Status/ACK Register
  [31] PATTERN_INT ro — Interrupt Pending Status from RX Pattern Matcher Module
  [30] TDMA_INT ro — Interrupt Pending Status from TDMA Scheduler
  [29] TSM_INT ro — Interrupt Pending Interrupt Indication from TSM (Timestamping) module
  [28] SRCFLT_WD_INT — Interrupt Pending Status for MAC Source Filtering Watchdog
  [27] EFP_INT — Interrupt from Extended Frame Parser
  [18:16] IRQ_MAC_EEE — Interrupt Pending Status per Line Port MAC Interrupt
  [10:8] IRQ_LINK — Interrupt Pending per Line Port Phy Link Change Interrupt
  [7] HUB_INT ro — Interrupt Pending Status from Hub Module
  [6] PRP_INT ro — Interrupt Pending Status from PRP Module
  [5] DLR_INT ro — Interrupt Pending Status from DLR Module
  [4] IRQ_TEST ro — Interrupt Status for IRQ_TEST
  [3] LK_NEW_SRC — Latched Interrupt Status for LK_NEW_SRC
  [1] MDIO1 — Latched Interrupt Status for MDIO1
  [0] IRQ_PEND ro — Interrupt Pending Status
{0x680+0x20*i} ATIME_CTRL{i} (i=0..1) — Timer {i} Control Register (n = 0, 1)
  [12] CAPTURE_ALL — Capture All Timers Value (Command Bit)
  [11] CAPTURE — Capture Time Value (Command Bit)
  [9] RESTART — Resets the Timer to Zero (Command Bit)
  [5] EVT_PERIOD_RST — Reset Timer on Periodical Event
  [4] EVT_PERIOD_ENA — Enable Periodical Event
  [2] EVT_OFFSET_ENA — Enable Offset Event
  [1] ONE_SHOT — Avoid timer wrap around. If set, the timer stops at maximum. An overflow interrupt (TSM_CONFIG.IRQ_ATIME_OVER) occurs (if enabled) when the maximum is reached.
  [0] ENABLE
{0x684+0x20*i} ATIME{i} (i=0..1) — Timer {i} Count Register (n = 0, 1)
  [31:0] TIMER_VAL — Timer Value
{0x688+0x20*i} ATIME_OFFSET{i} (i=0..1) — Timer {i} Offset Register (n = 0, 1)
  [31:0] OFFSET — Value used for performing offset corrections without changing the drift correction
{0x68C+0x20*i} ATIME_EVT_PERIOD{i} (i=0..1) reset 0x3B9ACA00 — Timer {i} Periodic Event Register (n = 0, 1)
  [31:0] PERIOD — Value for generating periodic events
{0x690+0x20*i} ATIME_CORR{i} (i=0..1) — Timer {i} Correction Period Register (n = 0, 1)
  [30:0] CORR_PERIOD — Correction Period
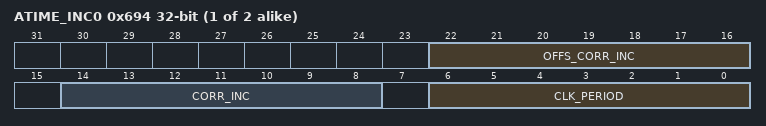
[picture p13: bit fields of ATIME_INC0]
{0x694+0x20*i} ATIME_INC{i} (i=0..1) — Timer {i} Increment Register (n = 0, 1)
  [22:16] OFFS_CORR_INC — Offset Correction Increment Value
  [14:8] CORR_INC — Correction Increment Value
  [6:0] CLK_PERIOD — Clock Period of the Timestamping Clock (125 MHz) in nanoseconds
{0x698+0x20*i} ATIME_SEC{i} (i=0..1) — Timer {i} Seconds Time Register (n = 0, 1)
  [31:0] SEC_TIME — Seconds Time Value
{0x69C+0x20*i} ATIME_OFFS_CORR{i} (i=0..1) — Timer {i} Offset Correction Counter Register (n = 0, 1)
  [31:0] OFFS_CORR_CNT — Offset Correction Counter
